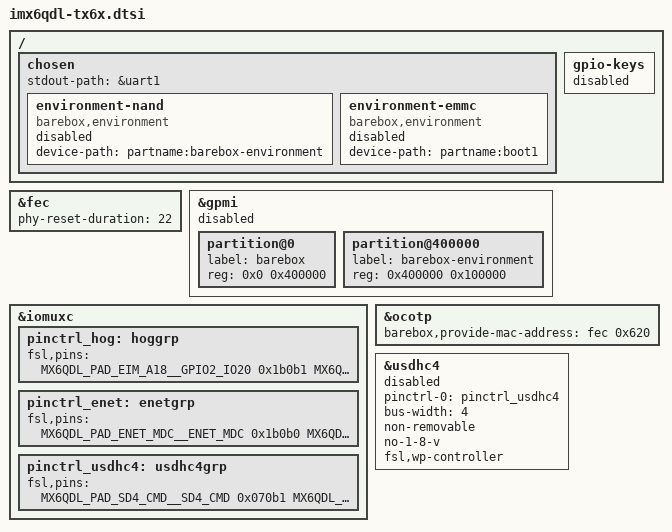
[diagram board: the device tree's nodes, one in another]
/ {
	chosen {
		stdout-path = &uart1;

		environment-nand {
			status = "disabled";
			compatible = "barebox,environment";
			device-path = &gpmi, "partname:barebox-environment";
		};

		environment-emmc {
			status = "disabled";
			compatible = "barebox,environment";
			device-path = &usdhc4, "partname:boot1";
		};
	};

	gpio-keys {
		status = "disabled";
	};
};

&fec {
	phy-reset-duration = <22>;
};

&gpmi {
	status = "disabled";

	partition@0 {
		label = "barebox";
		reg = <0x0 0x400000>;
	};

	partition@400000 {
		label = "barebox-environment";
		reg = <0x400000 0x100000>;
	};
};

&iomuxc {
	pinctrl_hog: hoggrp {
		fsl,pins = <
			MX6QDL_PAD_EIM_A18__GPIO2_IO20		0x1b0b1 /* LED */
			MX6QDL_PAD_SD3_DAT2__GPIO7_IO06		0x1b0b1 /* ETN PHY RESET */
			MX6QDL_PAD_SD3_DAT4__GPIO7_IO01		0x1b0b1 /* ETN PHY INT */
			MX6QDL_PAD_EIM_A25__GPIO5_IO02		0x1b0b1 /* PWR BTN */
			MX6QDL_PAD_EIM_D20__GPIO3_IO20		0x1b0b1 /* ETN PHY POWER */
		>;
	};

	pinctrl_enet: enetgrp {
		fsl,pins = <
			MX6QDL_PAD_ENET_MDC__ENET_MDC		0x1b0b0
			MX6QDL_PAD_ENET_MDIO__ENET_MDIO		0x1b0b0
			MX6QDL_PAD_ENET_RXD0__ENET_RX_DATA0	0x1b0b0
			MX6QDL_PAD_ENET_RXD1__ENET_RX_DATA1	0x1b0b0
			MX6QDL_PAD_ENET_RX_ER__ENET_RX_ER	0x1b0b0
			MX6QDL_PAD_ENET_TX_EN__ENET_TX_EN	0x1b0b0
			MX6QDL_PAD_ENET_TXD0__ENET_TX_DATA0	0x1b0b0
			MX6QDL_PAD_ENET_TXD1__ENET_TX_DATA1	0x1b0b0
			MX6QDL_PAD_ENET_CRS_DV__ENET_RX_EN	0x1b0b0
			MX6QDL_PAD_GPIO_16__ENET_REF_CLK	0x4001b0b0
		>;
	};

	pinctrl_usdhc4: usdhc4grp {
		fsl,pins = <
			MX6QDL_PAD_SD4_CMD__SD4_CMD		0x070b1
			MX6QDL_PAD_SD4_CLK__SD4_CLK		0x070b1
			MX6QDL_PAD_SD4_DAT0__SD4_DATA0		0x070b1
			MX6QDL_PAD_SD4_DAT1__SD4_DATA1		0x070b1
			MX6QDL_PAD_SD4_DAT2__SD4_DATA2		0x070b1
			MX6QDL_PAD_SD4_DAT3__SD4_DATA3		0x070b1
			MX6QDL_PAD_NANDF_ALE__SD4_RESET		0x0b0b1
		>;
	};
};

&ocotp {
	barebox,provide-mac-address = <&fec 0x620>;
};

&usdhc4 {
	pinctrl-names = "default";
	pinctrl-0 = <&pinctrl_usdhc4>;
	bus-width = <4>;
	non-removable;
	no-1-8-v;
	fsl,wp-controller;
	status = "disabled";
};
